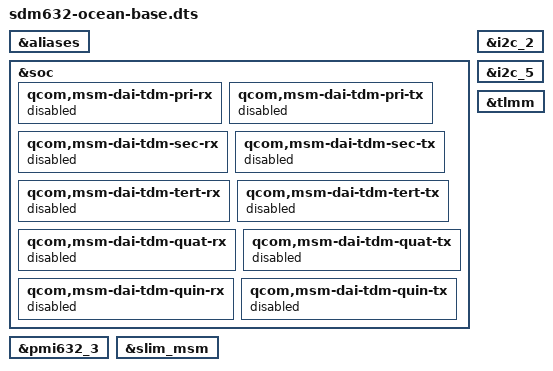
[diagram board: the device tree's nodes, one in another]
/* Copyright (c) 2018, The Linux Foundation. All rights reserved.
 *
 * This program is free software; you can redistribute it and/or modify
 * it under the terms of the GNU General Public License version 2 and
 * only version 2 as published by the Free Software Foundation.
 *
 * This program is distributed in the hope that it will be useful,
 * but WITHOUT ANY WARRANTY; without even the implied warranty of
 * MERCHANTABILITY or FITNESS FOR A PARTICULAR PURPOSE.  See the
 * GNU General Public License for more details.
 */

/dts-v1/;

#include "sdm632-moto-base.dtsi"

&aliases {
	/delete-property/ spi3;
};

&soc {
	/delete-node/ gpio_keys;
	/delete-node/ spi@78b7000;

	/delete-node/ sound;
	/delete-node/ sound-9335;
	/delete-node/ msm_cdc_pinctrl_us_euro_sw;
	/delete-node/ wsa881x_analog_vi_pctrl;
	/delete-node/ wsa881x_analog_clk_pctrl;
	/delete-node/ wsa881x_analog_reset_pctrl;
	/delete-node/ msm_cdc_pinctrl@67;

	qcom,msm-dai-tdm-pri-rx {
		status = "disabled";
	};
	qcom,msm-dai-tdm-pri-tx {
		status = "disabled";
	};
	qcom,msm-dai-tdm-sec-rx {
		status = "disabled";
	};
	qcom,msm-dai-tdm-sec-tx {
		status = "disabled";
	};
	qcom,msm-dai-tdm-tert-rx {
		status = "disabled";
	};
	qcom,msm-dai-tdm-tert-tx {
		status = "disabled";
	};
	qcom,msm-dai-tdm-quat-rx {
		status = "disabled";
	};
	qcom,msm-dai-tdm-quat-tx {
		status = "disabled";
	};
	qcom,msm-dai-tdm-quin-rx {
		status = "disabled";
	};
	qcom,msm-dai-tdm-quin-tx {
		status = "disabled";
	};
};

/* the node cannot be deleted from sdm450-ali-pinctrl.dtsi
&tlmm {
	/delete-node/ tlmm_gpio_key;
};
*/

&pmi632_3 {
	/delete-node/ qcom,vibrator@5700;
};

&i2c_2 {
	/delete-node/ wsa881x-i2c-codec@f;
	/delete-node/ wsa881x-i2c-codec@45;
};

&i2c_5 {
	/delete-property/ pinctrl-0;
	/delete-property/ pinctrl-1;
};

&slim_msm {
	/delete-node/ tasha_codec;
};

&tlmm {
	/delete-node/ nfc;
	/delete-node/ i2c_5;
	/delete-node/ wsa-vi;
	/delete-node/ wsa_reset;
	/delete-node/ wsa_clk;
	/delete-node/ cdc_reset_ctrl;
	/delete-node/ cross-conn-det;
};
/*
&thermal_zones {
	/delete-node/ pa-therm0;
	/delete-node/ quiet-therm-adc;
	/delete-node/ xo-therm-adc;
};*/

